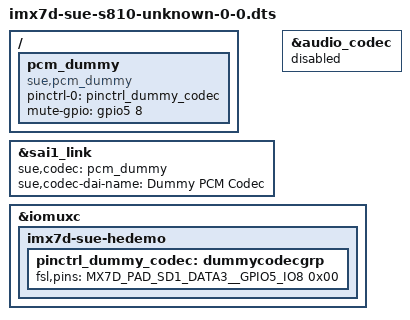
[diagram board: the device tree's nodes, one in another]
/*
 * This program is free software; you can redistribute it and/or modify
 * it under the terms of the GNU General Public License version 2 as
 * published by the Free Software Foundation.
 */

/dts-v1/;

#include "imx7d-sue-s810-0.dtsi"
#include "imx7d-sue-demo-0.dtsi"

/ {
	pcm_dummy: pcm_dummy {
		pinctrl-names = "default";
		pinctrl-0 = <&pinctrl_dummy_codec>;

		compatible = "sue,pcm_dummy";
		mute-gpio = <&gpio5 8 0>;
	};
};

&sai1_link {
	sue,codec = <&pcm_dummy>;
	sue,codec-dai-name = "Dummy PCM Codec";
};

&audio_codec {
	status = "disabled";
};

&iomuxc {
	imx7d-sue-hedemo {
		pinctrl_dummy_codec: dummycodecgrp {
			fsl,pins = <
				MX7D_PAD_SD1_DATA3__GPIO5_IO8	0x00	/* AMP mute */
			>;
		};
	};
};
